AUTOSAR XML (schema 4-2-1)
package /ComponentTypes
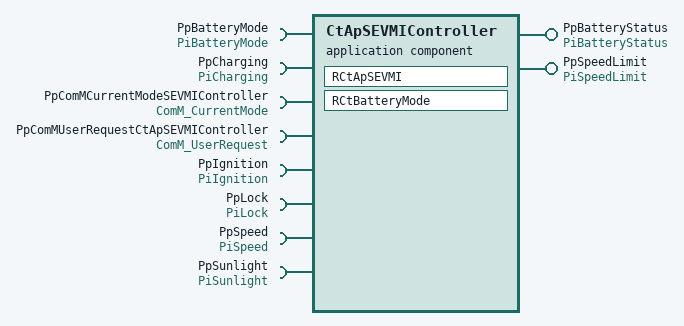
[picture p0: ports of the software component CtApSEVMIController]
  application sw component type CtApSEVMIController
    provide port PpBatteryStatus: nonqueued-sender-com-spec{data-element=DeBatteryStatus, init-value=constant-reference=CBatteryStatus}, provided-interface=PiBatteryStatus
    provide port PpSpeedLimit: nonqueued-sender-com-spec{data-element=DeSpeedLimit, init-value=constant-reference=CSpeedLimit}, provided-interface=PiSpeedLimit
    8 x require port:
      PpBatteryMode: mode-switch-receiver-com-spec{enhanced-mode-api=false, supports-asynchronous-mode-switch=false}, required-interface=PiBatteryMode
      PpCharging: nonqueued-receiver-com-spec{data-element=DeCharging, filter=data-filter-type=ALWAYS, init-value=constant-reference=CCharging}, required-interface=PiCharging
      PpComMCurrentModeSEVMIController: mode-switch-receiver-com-spec{enhanced-mode-api=false, supports-asynchronous-mode-switch=false}, required-interface=ComM_CurrentMode
      PpComMUserRequestCtApSEVMIController: required-interface=ComM_UserRequest
      PpIgnition: nonqueued-receiver-com-spec{data-element=DeIgnition, filter=data-filter-type=ALWAYS, init-value=constant-reference=CIgnition}, required-interface=PiIgnition
      PpLock: nonqueued-receiver-com-spec{data-element=DeLock, filter=data-filter-type=ALWAYS, init-value=constant-reference=CCarLocked}, required-interface=PiLock
      PpSpeed: required-interface=PiSpeed
      PpSunlight: nonqueued-receiver-com-spec{data-element=DeSunlight, filter=data-filter-type=ALWAYS, init-value=constant-reference=CSunlight}, required-interface=PiSunlight
    behavior CtApSEVMIController_InternalBehavior: data-type-mapping=ApMappingSet
      init event RCtApSEVMI_InitEvent: start-on-event=RCtApSEVMI
      swc mode switch event MST_RCtBatteryMode_0: start-on-event=RCtBatteryMode, activation=ON-ENTRY, mode=PpBatteryMode.BatteryModes.NORMAL
      runnable RCtApSEVMI
        data-receive-point-by-arguments:
          4 x access:
            REC_PpCharging_DeCharging: accessed-variable=PpCharging.DeCharging
            REC_PpIgnition_DeIgnition: accessed-variable=PpIgnition.DeIgnition
            REC_PpLock_DeLock: accessed-variable=PpLock.DeLock
            REC_PpSunlight_DeSunlight: accessed-variable=PpSunlight.DeSunlight
        data-send-points:
          access SEND_PpSpeedLimit_DeSpeedLimit: accessed-variable=PpSpeedLimit.DeSpeedLimit
        sync call SC_PpComMUserRequestCtApSEVMIController_RequestComMode: operation=PpComMUserRequestCtApSEVMIController.RequestComMode, timeout=0
        sync call SC_PpSpeed_ReadChannel: operation=PpSpeed.ReadChannel, timeout=0
      runnable RCtBatteryMode
        data-send-points:
          access SEND_PpBatteryStatus_DeBatteryStatus: accessed-variable=PpBatteryStatus.DeBatteryStatus
          access SEND_PpSpeedLimit_DeSpeedLimit: accessed-variable=PpSpeedLimit.DeSpeedLimit
  swc implementation CtApSEVMIController_Implementation: behavior=CtApSEVMIController_InternalBehavior
    code-descriptors:
      code Default: artifact-descriptors=autosar-engineering-object={short-label=Default, category=SWSRC}
